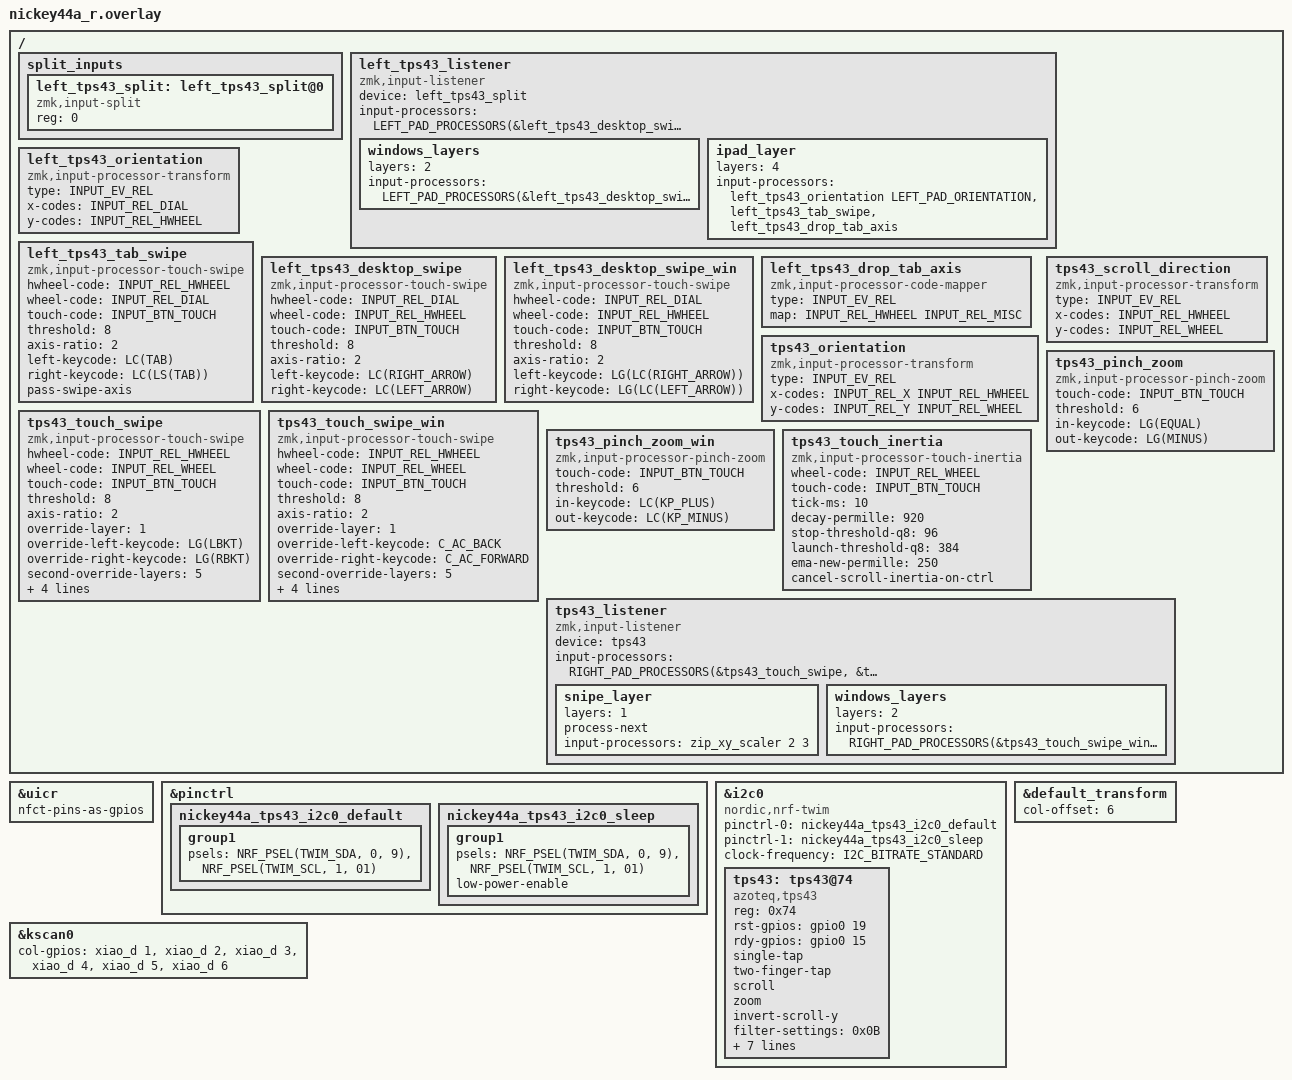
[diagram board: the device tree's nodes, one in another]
#include "nickey44a.dtsi"
#include <input/processors.dtsi>
#include <dt-bindings/pinctrl/nrf-pinctrl.h>
#include <dt-bindings/zmk/input_transform.h>
#include <dt-bindings/zmk/keys.h>
#include <zephyr/dt-bindings/input/input-event-codes.h>

/*
 * TPS43 FPC breakout wiring:
 *   SDA = XIAO NFC1/P0.09
 *   SCL = XIAO P1.01
 *   RDY = XIAO P0.15
 *   NRST = XIAO P0.19
 */

/*
 * Trackpad mounting, one setting per side. After changing it, rebuild and
 * flash the right half only: both pads are oriented here, on the central,
 * and the left half's firmware is the same for either mounting. The
 * gestures and their directions (see docs/dual-tps43.md) stay the same.
 *
 *   PAD_NOTCH_RIGHT  The notch of the TPS43 to the right, as in the build
 *                    guide. Uses the author's measured correction (e3004b7).
 *   PAD_NOTCH_LEFT   Turned 180 degrees from PAD_NOTCH_RIGHT, so the flat
 *                    cable is not twisted. Both axes are reversed.
 *
 * According to the author, the left case fits PAD_NOTCH_LEFT only after
 * modification. The right case fits it, but it comes close to the XIAO.
 */
#define PAD_NOTCH_RIGHT 0
#define PAD_NOTCH_LEFT 1
#define RIGHT_PAD_MOUNT PAD_NOTCH_RIGHT
#define LEFT_PAD_MOUNT PAD_NOTCH_RIGHT

/*
 * Right pad, applied to the cursor and to both scroll axes. The author
 * measured the controller output for PAD_NOTCH_RIGHT as left -> down and
 * down -> left. PAD_NOTCH_LEFT drops both inverts to turn that by 180 degrees.
 */
#if RIGHT_PAD_MOUNT == PAD_NOTCH_RIGHT
#define RIGHT_PAD_ORIENTATION \
    (INPUT_TRANSFORM_XY_SWAP | INPUT_TRANSFORM_X_INVERT | INPUT_TRANSFORM_Y_INVERT)
#else
#define RIGHT_PAD_ORIENTATION (INPUT_TRANSFORM_XY_SWAP)
#endif

/*
 * Left pad, as it arrives from the left half: REL_DIAL is the two-finger
 * left/right movement, REL_HWHEEL the two-finger up/down movement. This turns
 * them into right = positive and down = positive. The author measured that a
 * right swipe produces negative DIAL with PAD_NOTCH_RIGHT, so that mounting
 * inverts both; PAD_NOTCH_LEFT already has these signs.
 */
#if LEFT_PAD_MOUNT == PAD_NOTCH_RIGHT
#define LEFT_PAD_ORIENTATION (INPUT_TRANSFORM_X_INVERT | INPUT_TRANSFORM_Y_INVERT)
#else
#define LEFT_PAD_ORIENTATION 0
#endif

&uicr {
    nfct-pins-as-gpios;
};

&pinctrl {
    nickey44a_tps43_i2c0_default: nickey44a_tps43_i2c0_default {
        group1 {
            psels = <NRF_PSEL(TWIM_SDA, 0, 9)>,
                    <NRF_PSEL(TWIM_SCL, 1, 01)>;
        };
    };

    nickey44a_tps43_i2c0_sleep: nickey44a_tps43_i2c0_sleep {
        group1 {
            psels = <NRF_PSEL(TWIM_SDA, 0, 9)>,
                    <NRF_PSEL(TWIM_SCL, 1, 01)>;
            low-power-enable;
        };
    };
};

/ {
    split_inputs {
        #address-cells = <1>;
        #size-cells = <0>;

        left_tps43_split: left_tps43_split@0 {
            compatible = "zmk,input-split";
            reg = <0>;
        };
    };

    /*
     * Left pad: two-finger up/down switches tabs, two-finger left/right
     * moves between virtual desktops (Mac and Windows; nothing on the iPad,
     * which has none). Neither axis scrolls. The tab swipe lets its axis
     * through so that the desktop swipe sees both axes too, and
     * left_tps43_drop_tab_axis drops it at the end. Without the desktop
     * swipe, REL_DIAL reaches the listener, which ignores it.
     */
#define LEFT_PAD_PROCESSORS(desktop_swipe)                                         \
    <&left_tps43_orientation LEFT_PAD_ORIENTATION>, <&left_tps43_tab_swipe>,      \
    <desktop_swipe>, <&left_tps43_drop_tab_axis>

    left_tps43_listener: left_tps43_listener {
        compatible = "zmk,input-listener";
        device = <&left_tps43_split>;
        input-processors = LEFT_PAD_PROCESSORS(&left_tps43_desktop_swipe);

        /* WIN (layer 2), as on the right pad. */
        windows_layers {
            layers = <2>;
            input-processors = LEFT_PAD_PROCESSORS(&left_tps43_desktop_swipe_win);
        };

        /* IPAD (layer 4): tabs only. */
        ipad_layer {
            layers = <4>;
            input-processors = <&left_tps43_orientation LEFT_PAD_ORIENTATION>,
                               <&left_tps43_tab_swipe>, <&left_tps43_drop_tab_axis>;
        };
    };

    left_tps43_orientation: left_tps43_orientation {
        compatible = "zmk,input-processor-transform";
        #input-processor-cells = <1>;
        type = <INPUT_EV_REL>;
        x-codes = <INPUT_REL_DIAL>;
        y-codes = <INPUT_REL_HWHEEL>;
    };

    /*
     * Swipes on the up/down axis (HWHEEL), whose output it suppresses.
     * Finger up (negative) -> right tab, finger down -> left tab, like
     * scrolling down a list.
     */
    left_tps43_tab_swipe: left_tps43_tab_swipe {
        compatible = "zmk,input-processor-touch-swipe";
        #input-processor-cells = <0>;
        hwheel-code = <INPUT_REL_HWHEEL>;
        wheel-code = <INPUT_REL_DIAL>;
        touch-code = <INPUT_BTN_TOUCH>;
        threshold = <8>;
        axis-ratio = <2>;
        left-keycode = <LC(TAB)>;
        right-keycode = <LC(LS(TAB))>;
        pass-swipe-axis;
    };

    /*
     * Swipes on the left/right axis (DIAL), whose output it suppresses.
     * Finger right (positive) -> the desktop on the left, finger left -> the
     * one on the right, as with a three-finger swipe on a MacBook.
     * Ctrl+Left/Right moves between Spaces on macOS.
     */
    left_tps43_desktop_swipe: left_tps43_desktop_swipe {
        compatible = "zmk,input-processor-touch-swipe";
        #input-processor-cells = <0>;
        hwheel-code = <INPUT_REL_DIAL>;
        wheel-code = <INPUT_REL_HWHEEL>;
        touch-code = <INPUT_BTN_TOUCH>;
        threshold = <8>;
        axis-ratio = <2>;
        left-keycode = <LC(RIGHT_ARROW)>;
        right-keycode = <LC(LEFT_ARROW)>;
    };

    /* Win+Ctrl+Left/Right moves between virtual desktops on Windows. */
    left_tps43_desktop_swipe_win: left_tps43_desktop_swipe_win {
        compatible = "zmk,input-processor-touch-swipe";
        #input-processor-cells = <0>;
        hwheel-code = <INPUT_REL_DIAL>;
        wheel-code = <INPUT_REL_HWHEEL>;
        touch-code = <INPUT_BTN_TOUCH>;
        threshold = <8>;
        axis-ratio = <2>;
        left-keycode = <LG(LC(RIGHT_ARROW))>;
        right-keycode = <LG(LC(LEFT_ARROW))>;
    };

    /* The tab axis, passed by left_tps43_tab_swipe; the listener ignores MISC. */
    left_tps43_drop_tab_axis: left_tps43_drop_tab_axis {
        compatible = "zmk,input-processor-code-mapper";
        #input-processor-cells = <0>;
        type = <INPUT_EV_REL>;
        map = <INPUT_REL_HWHEEL INPUT_REL_MISC>;
    };

    tps43_orientation: tps43_orientation {
        compatible = "zmk,input-processor-transform";
        #input-processor-cells = <1>;
        type = <INPUT_EV_REL>;
        x-codes = <INPUT_REL_X INPUT_REL_HWHEEL>;
        y-codes = <INPUT_REL_Y INPUT_REL_WHEEL>;
    };

    /*
     * After the orientation, finger down is positive WHEEL, as for the
     * cursor. Invert it so that finger up scrolls up, which hosts with
     * natural scrolling on (Mac, and the Windows mouse setting reversed)
     * turn into the content following the finger, as on a MacBook.
     * RIGHT_PAD_PROCESSORS also inverts HWHEEL with it after the swipe, so
     * that finger right scrolls the same way as on the left pad.
     */
    tps43_scroll_direction: tps43_scroll_direction {
        compatible = "zmk,input-processor-transform";
        #input-processor-cells = <1>;
        type = <INPUT_EV_REL>;
        x-codes = <INPUT_REL_HWHEEL>;
        y-codes = <INPUT_REL_WHEEL>;
    };

    /*
     * Two fingers left/right scroll horizontally (no base keycodes). Only
     * with Space held (MOUSE_SLOW, layer 1) or LANG2 held (NUM, layer 5) do
     * they swipe; the left pad switches tabs and desktops.
     *
     * Physical right swipe is negative after the orientation correction.
     * On layer 1, finger right -> back, left -> forward, as on a MacBook.
     * While NUM is held, it is the app switcher on every host: the first
     * swipe sends Tab with the switcher's modifier (Cmd, or Alt on Windows)
     * and keeps the modifier pressed until the finger lifts; each further
     * swipe in the same touch moves the selection, finger left -> right
     * (Tab), right -> left (Shift+Tab). Lifting the finger switches to the
     * selected app, so apps further back than the last one are reached.
     *
     * macOS ignores the Browser Back/Forward keys, so the Mac profile sends
     * Cmd+[ and Cmd+], which go back and forward in Safari, Chrome and
     * Finder. The Windows profiles use tps43_touch_swipe_win instead. The
     * iPad takes these Mac keys, so the right pad has no iPad chain.
     */
    tps43_touch_swipe: tps43_touch_swipe {
        compatible = "zmk,input-processor-touch-swipe";
        #input-processor-cells = <0>;
        hwheel-code = <INPUT_REL_HWHEEL>;
        wheel-code = <INPUT_REL_WHEEL>;
        touch-code = <INPUT_BTN_TOUCH>;
        threshold = <8>;
        axis-ratio = <2>;
        override-layer = <1>;
        override-left-keycode = <LG(LBKT)>;
        override-right-keycode = <LG(RBKT)>;
        second-override-layers = <5>;
        second-override-left-keycode = <LS(TAB)>;
        second-override-right-keycode = <TAB>;
        second-override-hold-keycode = <LEFT_GUI>;
        /* Travel per further app; the first swipe needs only threshold. */
        second-override-repeat-threshold = <24>;
    };

    /* tps43_touch_swipe for Windows, where Browser Back/Forward work. */
    tps43_touch_swipe_win: tps43_touch_swipe_win {
        compatible = "zmk,input-processor-touch-swipe";
        #input-processor-cells = <0>;
        hwheel-code = <INPUT_REL_HWHEEL>;
        wheel-code = <INPUT_REL_WHEEL>;
        touch-code = <INPUT_BTN_TOUCH>;
        threshold = <8>;
        axis-ratio = <2>;
        override-layer = <1>;
        override-left-keycode = <C_AC_BACK>;
        override-right-keycode = <C_AC_FORWARD>;
        /* Alt+Tab is the app switcher on Windows. */
        second-override-layers = <5>;
        second-override-left-keycode = <LS(TAB)>;
        second-override-right-keycode = <TAB>;
        second-override-hold-keycode = <LEFT_ALT>;
        second-override-repeat-threshold = <24>;
    };

    /*
     * Pinch on the right pad (`zoom;` on the tps43 node): spreading the
     * fingers zooms in and closing them zooms out, one key per threshold.
     * A whole pinch measured 10 to 20 on 2026-11-24, so about 2 or 3 steps.
     * The pad is a mouse to the host, which has no pinch, so these are keys.
     * Mac and iPad: Cmd+= / Cmd+-. Windows: Ctrl and the keypad + / -,
     * which are the same keys on US and JIS layouts.
     */
    tps43_pinch_zoom: tps43_pinch_zoom {
        compatible = "zmk,input-processor-pinch-zoom";
        #input-processor-cells = <0>;
        touch-code = <INPUT_BTN_TOUCH>;
        threshold = <6>;
        in-keycode = <LG(EQUAL)>;
        out-keycode = <LG(MINUS)>;
    };

    tps43_pinch_zoom_win: tps43_pinch_zoom_win {
        compatible = "zmk,input-processor-pinch-zoom";
        #input-processor-cells = <0>;
        touch-code = <INPUT_BTN_TOUCH>;
        threshold = <6>;
        in-keycode = <LC(KP_PLUS)>;
        out-keycode = <LC(KP_MINUS)>;
    };

    tps43_touch_inertia: tps43_touch_inertia {
        compatible = "zmk,input-processor-touch-inertia";
        #input-processor-cells = <0>;
        wheel-code = <INPUT_REL_WHEEL>;
        touch-code = <INPUT_BTN_TOUCH>;
        tick-ms = <10>;
        decay-permille = <920>;
        stop-threshold-q8 = <96>;
        launch-threshold-q8 = <384>;
        ema-new-permille = <250>;
        cancel-scroll-inertia-on-ctrl;
    };

/*
 * Enter AUTO_MOUSE (layer 8 in config/nickey44a.keymap) for 800 ms, as on
 * tomkey, then orient the pad and recognize pinches and swipes. The
 * horizontal scrolling that the swipe lets through is inverted after it,
 * so that the swipe directions above stay as they are.
 */
#define RIGHT_PAD_PROCESSORS(swipe, pinch)                                         \
    <&zip_temp_layer 8 800>, <&tps43_orientation RIGHT_PAD_ORIENTATION>,          \
    <&tps43_scroll_direction INPUT_TRANSFORM_Y_INVERT>, <pinch>, <swipe>,         \
    <&tps43_scroll_direction INPUT_TRANSFORM_X_INVERT>, <&tps43_touch_inertia>

    tps43_listener: tps43_listener {
        compatible = "zmk,input-listener";
        device = <&tps43>;
        input-processors = RIGHT_PAD_PROCESSORS(&tps43_touch_swipe, &tps43_pinch_zoom);

        snipe_layer {
            layers = <1>;
            process-next;
            input-processors = <&zip_xy_scaler 2 3>;
        };

        /*
         * WIN (layer 2 in config/nickey44a.keymap), on for both Windows
         * profiles. Without process-next, this chain runs instead of the one
         * above.
         */
        windows_layers {
            layers = <2>;
            input-processors = RIGHT_PAD_PROCESSORS(&tps43_touch_swipe_win, &tps43_pinch_zoom_win);
        };
    };
};

&i2c0 {
    status = "okay";
    compatible = "nordic,nrf-twim";
    pinctrl-0 = <&nickey44a_tps43_i2c0_default>;
    pinctrl-1 = <&nickey44a_tps43_i2c0_sleep>;
    pinctrl-names = "default", "sleep";
    clock-frequency = <I2C_BITRATE_STANDARD>;
    #address-cells = <1>;
    #size-cells = <0>;

    tps43: tps43@74 {
        compatible = "azoteq,tps43";
        reg = <0x74>;
        rst-gpios = <&gpio0 19 GPIO_ACTIVE_HIGH>;
        rdy-gpios = <&gpio0 15 GPIO_ACTIVE_HIGH>;

        single-tap;
        two-finger-tap;
        scroll;
        /* Pinch, reported as INPUT_REL_MISC for tps43_pinch_zoom. */
        zoom;
        /* The listener swaps axes, so driver X controls host vertical scrolling. */
        invert-scroll-y;

        filter-settings = <0x0B>;
        filter-dynamic-bottom = <5>;
        sensitivity = <100>;
        scroll-sensitivity = <5>;
        hold-time = <250>;
        enable-power-management;
        /* Controller settings used when the listener's correction was measured. */
        switch-xy;
        invert-x;
    };
};

&default_transform {
    col-offset = <6>;
};

&kscan0 {
        col-gpios
            = <&xiao_d 1 GPIO_ACTIVE_HIGH>
            , <&xiao_d 2 GPIO_ACTIVE_HIGH>
            , <&xiao_d 3 GPIO_ACTIVE_HIGH>
            , <&xiao_d 4 GPIO_ACTIVE_HIGH>
            , <&xiao_d 5 GPIO_ACTIVE_HIGH>
            , <&xiao_d 6 GPIO_ACTIVE_HIGH>
            ;
};
